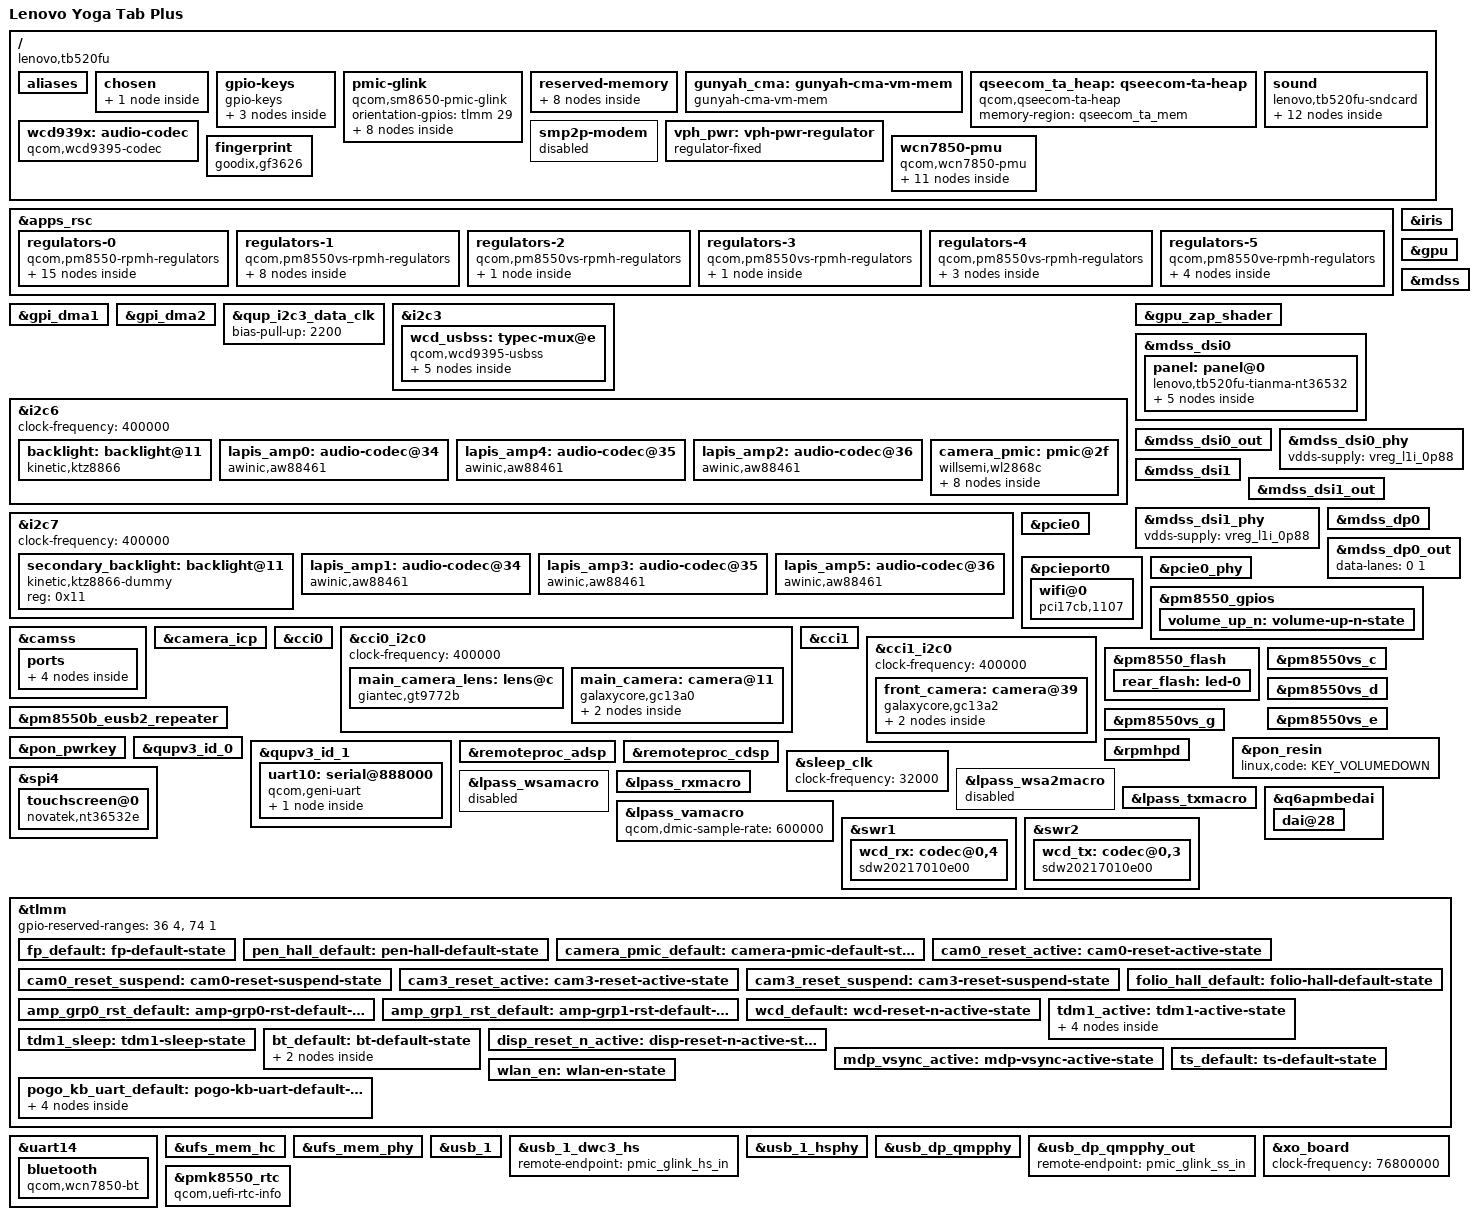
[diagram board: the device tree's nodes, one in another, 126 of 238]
// SPDX-License-Identifier: BSD-3-Clause
/*
 * Device Tree for Lenovo Yoga Tab Plus / YOGA Pad Pro (TB520FU, codename "lapis")
 * SoC: Qualcomm Snapdragon 8 Gen 3 Wi-Fi (APQ8650 / SM8650P, "pineapplep")
 *
 * Translated from Lenovo ZUI_18.5.10.037_260929_ROW downstream DTB/DTBO
 * (dtb_06 PineappleP v2 + dtbo_37 Lapis QRD) onto the mainline SM8650 /
 * Osilvfe caihong-v7.3 architecture.
 */

/dts-v1/;

#include <dt-bindings/arm/qcom,ids.h>
#include <dt-bindings/regulator/qcom,rpmh-regulator.h>
#include <dt-bindings/clock/qcom,sm8650-camcc.h>
#include <dt-bindings/gpio/gpio.h>
#include <dt-bindings/input/input.h>
#include <dt-bindings/leds/common.h>
#include <dt-bindings/sound/qcom,q6dsp-lpass-ports.h>
#include "sm8650.dtsi"
#include "pm8550.dtsi"
#include "pm8550b.dtsi"
#define PMK8550VE_SID 8
#include "pm8550ve.dtsi"
#include "pm8550vs.dtsi"
#include "pmk8550.dtsi"

/* Override upstream memory carveouts that differ on Lenovo lapis */
/delete-node/ &adspslpi_mem;
/delete-node/ &hwfence_shbuf;

/* Reclaim downstream Android Gunyah / QDSS reusable regions */
/delete-node/ &trust_ui_vm_mem;
/delete-node/ &oem_vm_mem;
/delete-node/ &qdss_mem;

/ {
	model = "Lenovo Yoga Tab Plus";
	compatible = "lenovo,tb520fu", "qcom,sm8650";
	chassis-type = "tablet";

	/* Lenovo ABL refuses to boot a DTB that does not match lapis QRD */
	qcom,msm-id = <QCOM_ID_SM8650 0x20000>, <QCOM_ID_SM8650 0x10000>,
		      <577 0x20000>, <577 0x10000>;
	qcom,board-id = <QCOM_BOARD_ID(QRD, 2, 0) 0>;

	/*
	 * Lenovo ABL compares this against the region stored on the device and
	 * powers off ("not compatible with hardware") if it is missing or differs.
	 */
	region_country = "ROW";

	aliases {
		serial0 = &uart15;
		serial1 = &uart14;
		serial2 = &uart10;
	};

	chosen {
		#address-cells = <2>;
		#size-cells = <2>;
		ranges;

		/*
		 * Phase 1 early bring-up framebuffer (ABL cont_splash_region):
		 * Enable status = "okay" below (and disable &mdss) when booting a
		 * headless/initramfs kernel before loading the NT36532 DRM panel driver.
		 * Resolution: 2944x1840 (or portrait 1840x2944 depending on ABL scanout),
		 * 32 bpp at physical address 0xd5100000 (carveout 0x2b00000).
		 */
		framebuffer0: framebuffer@d5100000 {
			compatible = "simple-framebuffer";
			reg = <0x0 0xd5100000 0x0 (2944 * 1840 * 4)>;
			width = <2944>;
			height = <1840>;
			stride = <(2944 * 4)>;
			format = "a8r8g8b8";
			memory-region = <&cont_splash_mem>;
			status = "disabled";
		};
	};

	/*
	 * No /hypervisor node. Gunyah recovers the resource-manager
	 * capabilities from XBL's merged tree (they change every boot), and
	 * a node at this path makes userspace treat the tablet as a VM.
	 */

	gpio-keys {
		compatible = "gpio-keys";

		pinctrl-0 = <&volume_up_n>, <&pen_hall_default>, <&folio_hall_default>;
		pinctrl-names = "default";

		key-volume-up {
			label = "Volume Up";
			linux,code = <KEY_VOLUMEUP>;
			gpios = <&pm8550_gpios 6 GPIO_ACTIVE_LOW>;
			debounce-interval = <15>;
			linux,can-disable;
			wakeup-source;
		};

		/*
		 * Downstream hall_detect@0 has two Hall sensors, TLMM 177 and
		 * 182. GPIO 177 goes low when the pen is docked on the tablet
		 * edge (verified on hardware), so it must not be reported as a
		 * lid switch: that makes userspace treat the built-in panel as
		 * closed whenever the pen is attached.
		 */
		event-hall-pen {
			label = "Pen Dock Hall Switch";
			gpios = <&tlmm 177 GPIO_ACTIVE_LOW>;
			linux,input-type = <EV_SW>;
			linux,code = <SW_PEN_INSERTED>;
			linux,can-disable;
		};

		/*
		 * GPIO 182 is the second stock Hall line (0xb6). Treated as the
		 * folio/cover lid; confirm with a magnetic cover before relying
		 * on logind HandleLidSwitch (keep ignore until verified).
		 */
		event-hall-folio {
			label = "Folio Cover Hall Switch";
			gpios = <&tlmm 182 GPIO_ACTIVE_LOW>;
			linux,input-type = <EV_SW>;
			linux,code = <SW_LID>;
			linux,can-disable;
			wakeup-source;
		};
	};

	/*
	 * Lenovo uses standard 45W USB-PD via Qualcomm SMB1396/PM8550B + ADSP battmgr
	 * (no proprietary SuperVOOC overrides needed).
	 */
	pmic-glink {
		compatible = "qcom,sm8650-pmic-glink",
			     "qcom,sm8550-pmic-glink",
			     "qcom,pmic-glink";
		#address-cells = <1>;
		#size-cells = <0>;
		orientation-gpios = <&tlmm 29 GPIO_ACTIVE_HIGH>;

		connector@0 {
			compatible = "usb-c-connector";
			reg = <0>;

			power-role = "dual";
			data-role = "dual";

			ports {
				#address-cells = <1>;
				#size-cells = <0>;

				port@0 {
					reg = <0>;

					pmic_glink_hs_in: endpoint {
						remote-endpoint = <&usb_1_dwc3_hs>;
					};
				};

				port@1 {
					reg = <1>;

					pmic_glink_ss_in: endpoint {
						remote-endpoint = <&usb_dp_qmpphy_out>;
					};
				};

				port@2 {
					reg = <2>;

					pmic_glink_sbu: endpoint {
						remote-endpoint = <&wcd_usbss_sbu_mux>;
					};
				};
			};
		};
	};

	reserved-memory {
		/*
		 * Downstream lost_reg_mem / ramoops carveouts from live_merged.dts
		 * (dtb_06 + dtbo_37). Missing no-map here lets the kernel map
		 * TrustZone/HYP-protected pages and can reset abl back to fastboot.
		 */
		lost_reg_mem: lost-reg-mem@9b09c000 {
			reg = <0x0 0x9b09c000 0x0 0x4000>;
			no-map;
		};

		ramoops@a2000000 {
			compatible = "ramoops";
			reg = <0x0 0xa2000000 0x0 0x400000>;
			console-size = <0x200000>;
			pmsg-size = <0x200000>;
			no-map;
		};

		/* Exact Lenovo lapis ADSP/SLPI carveout from dtb_06.dts (0x4080000) */
		adspslpi_mem: adspslpi@9df00000 {
			reg = <0x0 0x9df00000 0x0 0x4080000>;
			no-map;
		};

		/* Exact Lenovo lapis hwfence carveout from dtb_06.dts */
		hwfence_shbuf: hwfence-shbuf@d4e23000 {
			reg = <0x0 0xd4e23000 0x0 0x2dd000>;
			no-map;
		};

		/*
		 * Bootloader splash carveout from dtbo_37.dts fragment@73:
		 * reg = <0x0 0xd5100000 0x0 0x2b00000>;
		 * Keep reserved while testing simple-framebuffer; can be dropped once
		 * full DPU/NT36532 KMS takes over scanout cleanly.
		 */
		/*
		 * ABL looks this up by the exact path /reserved-memory/splash_region
		 * and powers the panel down before jumping to Linux if it is absent.
		 */
		cont_splash_mem: splash_region {
			label = "cont_splash_region";
			reg = <0x0 0xd5100000 0x0 0x2b00000>;
			no-map;
		};

		/* Exact Lenovo TZ merged region from dtb_06.dts */
		tz_merged_mem: tz-merged@d8000000 {
			reg = <0x0 0xd8000000 0x0 0x800000>;
			no-map;
		};

		gunyah_cma_mem: gunyah-cma-mem {
			compatible = "shared-dma-pool";
			alloc-ranges = <0x0 0x0 0x0 0xffffffff>;
			size = <0x0 0x4000000>;
			alignment = <0x0 0x200000>;
			reusable;
		};

		/*
		 * Staging heap for QSEE trusted-app images. The secure world
		 * accepts an image only from a 4 MiB-aligned region that has
		 * been shared as a whole, which is how Android's qseecom
		 * driver publishes qseecom_ta_region (16 MiB).
		 */
		qseecom_ta_mem: qseecom-ta-region {
			compatible = "shared-dma-pool";
			alloc-ranges = <0x0 0x0 0x0 0xffffffff>;
			size = <0x0 0x1000000>;
			alignment = <0x0 0x400000>;
			reusable;
		};
	};

	gunyah_cma: gunyah-cma-vm-mem {
		compatible = "gunyah-cma-vm-mem";
		memory-region = <&gunyah_cma_mem>;
		memory-region-names = "system-cma";
	};

	qseecom_ta_heap: qseecom-ta-heap {
		compatible = "qcom,qseecom-ta-heap";
		memory-region = <&qseecom_ta_mem>;
	};

	/*
	 * 6-Speaker Harman Kardon Audio (4 Woofers + 2 Tweeters):
	 * Driven by 6x Awinic AW882xx SmartPAs over Secondary TDM (SECONDARY_TDM_RX_0)
	 * + Qualcomm WCD939x SoundWire headset/USB-C analog codec + DMICs.
	 *
	 * Channel map from dtbo_37.dts fragments @64 & @65:
	 *   &i2c6: 0x34 -> ch0, 0x36 -> ch2, 0x35 -> ch4 (shared reset GPIO 128)
	 *   &i2c7: 0x34 -> ch1, 0x35 -> ch3, 0x36 -> ch5 (shared reset GPIO 28)
	 */
	sound {
		compatible = "lenovo,tb520fu-sndcard", "qcom,sm8650-sndcard";
		model = "Lenovo-TB520FU";
		audio-routing = "IN1_HPHL", "HPHL_OUT",
				"IN2_HPHR", "HPHR_OUT",
				"AMIC1", "MIC BIAS1",
				"AMIC3", "MIC BIAS3",
				"AMIC4", "MIC BIAS4",
				"AMIC5", "MIC BIAS3",
				"TX SWR_INPUT0", "ADC1_OUTPUT",
				"TX SWR_INPUT1", "ADC2_OUTPUT",
				"TX SWR_INPUT2", "ADC3_OUTPUT",
				"TX SWR_INPUT3", "ADC4_OUTPUT";

		wcd-playback-dai-link {
			link-name = "WCD Playback";

			cpu {
				sound-dai = <&q6apmbedai RX_CODEC_DMA_RX_0>;
			};

			codec {
				sound-dai = <&wcd939x 0>, <&swr1 0>, <&lpass_rxmacro 0>;
			};

			platform {
				sound-dai = <&q6apm>;
			};
		};

		wcd-capture-dai-link {
			link-name = "WCD Capture";

			cpu {
				sound-dai = <&q6apmbedai TX_CODEC_DMA_TX_3>;
			};

			codec {
				sound-dai = <&wcd939x 1>, <&swr2 0>, <&lpass_txmacro 0>;
			};

			platform {
				sound-dai = <&q6apm>;
			};
		};

		tdm-speaker-dai-link {
			link-name = "Secondary TDM Speakers";

			cpu {
				sound-dai = <&q6apmbedai SECONDARY_TDM_RX_0>;
			};

			codec {
				sound-dai = <&lapis_amp0>, <&lapis_amp1>,
					    <&lapis_amp2>, <&lapis_amp3>,
					    <&lapis_amp4>, <&lapis_amp5>;
			};

			platform {
				sound-dai = <&q6apm>;
			};
		};
	};

	wcd939x: audio-codec {
		compatible = "qcom,wcd9395-codec", "qcom,wcd9390-codec";

		pinctrl-0 = <&wcd_default>;
		pinctrl-names = "default";

		qcom,micbias1-microvolt = <1800000>;
		qcom,micbias2-microvolt = <1800000>;
		qcom,micbias3-microvolt = <1800000>;
		qcom,micbias4-microvolt = <1800000>;
		qcom,mbhc-buttons-vthreshold-microvolt = <75000 150000 237000 500000
							 500000 500000 500000 500000>;
		qcom,mbhc-headset-vthreshold-microvolt = <1700000>;
		qcom,mbhc-headphone-vthreshold-microvolt = <50000>;
		qcom,rx-device = <&wcd_rx>;
		qcom,tx-device = <&wcd_tx>;

		reset-gpios = <&tlmm 107 GPIO_ACTIVE_LOW>;

		vdd-buck-supply = <&vreg_l15b_1p8>;
		vdd-rxtx-supply = <&vreg_l15b_1p8>;
		vdd-io-supply = <&vreg_l15b_1p8>;
		vdd-mic-bias-supply = <&vreg_bob1>;

		#sound-dai-cells = <1>;
	};

	/* APQ8650 / SM8650P Wi-Fi-only tablet: disable cellular modem SMP2P */
	smp2p-modem {
		status = "disabled";
	};

	vph_pwr: vph-pwr-regulator {
		compatible = "regulator-fixed";

		regulator-name = "vph_pwr";
		regulator-min-microvolt = <3700000>;
		regulator-max-microvolt = <3700000>;

		regulator-always-on;
		regulator-boot-on;
	};

	/* Qualcomm FastConnect 7800 (WCN7850 / "kiwi_v2") PMU */
	wcn7850-pmu {
		compatible = "qcom,wcn7850-pmu";

		pinctrl-names = "default";
		pinctrl-0 = <&wlan_en>, <&bt_default>;

		wlan-enable-gpios = <&tlmm 16 GPIO_ACTIVE_HIGH>;
		bt-enable-gpios = <&tlmm 17 GPIO_ACTIVE_HIGH>;

		vdd-supply = <&vreg_s4i_0p85>;
		vddio-supply = <&vreg_l15b_1p8>;
		vddio1p2-supply = <&vreg_l3c_1p2>;
		vddaon-supply = <&vreg_s2c_0p8>;
		vdddig-supply = <&vreg_s3c_0p9>;
		vddrfa1p2-supply = <&vreg_s1c_1p2>;
		vddrfa1p8-supply = <&vreg_s6c_1p8>;

		clocks = <&rpmhcc RPMH_RF_CLK1>;

		regulators {
			vreg_pmu_rfa_cmn: ldo0 {
				regulator-name = "vreg_pmu_rfa_cmn";
			};

			vreg_pmu_aon_0p59: ldo1 {
				regulator-name = "vreg_pmu_aon_0p59";
			};

			vreg_pmu_wlcx_0p8: ldo2 {
				regulator-name = "vreg_pmu_wlcx_0p8";
			};

			vreg_pmu_wlmx_0p85: ldo3 {
				regulator-name = "vreg_pmu_wlmx_0p85";
			};

			vreg_pmu_btcmx_0p85: ldo4 {
				regulator-name = "vreg_pmu_btcmx_0p85";
			};

			vreg_pmu_rfa_0p8: ldo5 {
				regulator-name = "vreg_pmu_rfa_0p8";
			};

			vreg_pmu_rfa_1p2: ldo6 {
				regulator-name = "vreg_pmu_rfa_1p2";
			};

			vreg_pmu_rfa_1p8: ldo7 {
				regulator-name = "vreg_pmu_rfa_1p8";
			};

			vreg_pmu_pcie_0p9: ldo8 {
				regulator-name = "vreg_pmu_pcie_0p9";
			};

			vreg_pmu_pcie_1p8: ldo9 {
				regulator-name = "vreg_pmu_pcie_1p8";
			};
		};
	};
};

/*
 * All regulator voltage limits below match Lenovo's dtb_06.dts + dtbo_37.dts
 * ground truth to the exact microvolt.
 */
&apps_rsc {
	regulators-0 {
		compatible = "qcom,pm8550-rpmh-regulators";

		vdd-bob1-supply = <&vph_pwr>;
		vdd-bob2-supply = <&vph_pwr>;
		vdd-l2-l13-l14-supply = <&vreg_bob1>;
		vdd-l3-supply = <&vreg_s1c_1p2>;
		vdd-l5-l16-supply = <&vreg_bob1>;
		vdd-l6-l7-supply = <&vreg_bob1>;
		vdd-l8-l9-supply = <&vreg_bob1>;
		vdd-l11-supply = <&vreg_s1c_1p2>;
		vdd-l12-supply = <&vreg_s6c_1p8>;
		vdd-l15-supply = <&vreg_s6c_1p8>;
		vdd-l17-supply = <&vreg_bob2>;

		qcom,pmic-id = "b";

		vreg_bob1: bob1 {
			regulator-name = "vreg_bob1";
			regulator-min-microvolt = <3008000>;
			regulator-max-microvolt = <3960000>;
			regulator-initial-mode = <RPMH_REGULATOR_MODE_HPM>;
		};

		vreg_bob2: bob2 {
			regulator-name = "vreg_bob2";
			regulator-min-microvolt = <2704000>;
			regulator-max-microvolt = <3008000>;
			regulator-initial-mode = <RPMH_REGULATOR_MODE_HPM>;
		};

		vreg_l1b_1p8: ldo1 {
			regulator-name = "vreg_l1b_1p8";
			regulator-min-microvolt = <1800000>;
			regulator-max-microvolt = <1800000>;
			regulator-initial-mode = <RPMH_REGULATOR_MODE_HPM>;
			regulator-always-on;
		};

		vreg_l2b_3p0: ldo2 {
			regulator-name = "vreg_l2b_3p0";
			regulator-min-microvolt = <3008000>;
			regulator-max-microvolt = <3008000>;
			regulator-initial-mode = <RPMH_REGULATOR_MODE_HPM>;
			regulator-allow-set-load;
			regulator-allowed-modes = <RPMH_REGULATOR_MODE_LPM
						   RPMH_REGULATOR_MODE_HPM>;
		};

		vreg_l5b_3p1: ldo5 {
			regulator-name = "vreg_l5b_3p1";
			regulator-min-microvolt = <3104000>;
			regulator-max-microvolt = <3104000>;
			regulator-initial-mode = <RPMH_REGULATOR_MODE_HPM>;
			regulator-allow-set-load;
			regulator-allowed-modes = <RPMH_REGULATOR_MODE_LPM
						   RPMH_REGULATOR_MODE_HPM>;
		};

		vreg_l8b_1p8: ldo8 {
			regulator-name = "vreg_l8b_1p8";
			regulator-min-microvolt = <1800000>;
			regulator-max-microvolt = <3008000>;
			regulator-initial-mode = <RPMH_REGULATOR_MODE_HPM>;
			regulator-allow-set-load;
			regulator-allowed-modes = <RPMH_REGULATOR_MODE_LPM
						   RPMH_REGULATOR_MODE_HPM>;
		};

		vreg_l9b_2p96: ldo9 {
			regulator-name = "vreg_l9b_2p96";
			regulator-min-microvolt = <2960000>;
			regulator-max-microvolt = <3008000>;
			regulator-initial-mode = <RPMH_REGULATOR_MODE_HPM>;
			regulator-allow-set-load;
			regulator-allowed-modes = <RPMH_REGULATOR_MODE_LPM
						   RPMH_REGULATOR_MODE_HPM>;
		};

		vreg_l10b_1p8: ldo10 {
			regulator-name = "vreg_l10b_1p8";
			regulator-min-microvolt = <1800000>;
			regulator-max-microvolt = <1800000>;
			regulator-initial-mode = <RPMH_REGULATOR_MODE_HPM>;
			regulator-allow-set-load;
			regulator-allowed-modes = <RPMH_REGULATOR_MODE_LPM
						   RPMH_REGULATOR_MODE_HPM>;
		};

		/* Panel VDD (1.2 V) */
		vreg_l11b_1p2: ldo11 {
			regulator-name = "vreg_l11b_1p2";
			regulator-min-microvolt = <1200000>;
			regulator-max-microvolt = <1200000>;
			regulator-initial-mode = <RPMH_REGULATOR_MODE_HPM>;
			regulator-allow-set-load;
			regulator-allowed-modes = <RPMH_REGULATOR_MODE_LPM
						   RPMH_REGULATOR_MODE_HPM>;
		};

		/*
		 * Panel VDDIO. Stock Android votes 1.952 V, but L12B is fed from
		 * S6C (1.856 V) and enabling it at 1.952 V hard-resets the SoC.
		 */
		vreg_l12b_1p8: ldo12 {
			regulator-name = "vreg_l12b_1p8";
			regulator-min-microvolt = <1800000>;
			regulator-max-microvolt = <1800000>;
			regulator-initial-mode = <RPMH_REGULATOR_MODE_HPM>;
			regulator-allow-set-load;
			regulator-allowed-modes = <RPMH_REGULATOR_MODE_LPM
						   RPMH_REGULATOR_MODE_HPM>;
		};

		/* Panel VCI (3.0 V) */
		vreg_l13b_3p0: ldo13 {
			regulator-name = "vreg_l13b_3p0";
			regulator-min-microvolt = <3000000>;
			regulator-max-microvolt = <3000000>;
			regulator-initial-mode = <RPMH_REGULATOR_MODE_HPM>;
			regulator-allow-set-load;
			regulator-allowed-modes = <RPMH_REGULATOR_MODE_LPM
						   RPMH_REGULATOR_MODE_HPM>;
		};

		vreg_l14b_3p2: ldo14 {
			regulator-name = "vreg_l14b_3p2";
			regulator-min-microvolt = <3200000>;
			regulator-max-microvolt = <3200000>;
			regulator-initial-mode = <RPMH_REGULATOR_MODE_HPM>;
			regulator-always-on;
		};

		vreg_l15b_1p8: ldo15 {
			regulator-name = "vreg_l15b_1p8";
			regulator-min-microvolt = <1800000>;
			regulator-max-microvolt = <1800000>;
			regulator-initial-mode = <RPMH_REGULATOR_MODE_HPM>;
			regulator-allow-set-load;
			regulator-allowed-modes = <RPMH_REGULATOR_MODE_LPM
						   RPMH_REGULATOR_MODE_HPM>;
		};

		vreg_l16b_2p8: ldo16 {
			regulator-name = "vreg_l16b_2p8";
			regulator-min-microvolt = <2800000>;
			regulator-max-microvolt = <2800000>;
			regulator-initial-mode = <RPMH_REGULATOR_MODE_HPM>;
			regulator-allow-set-load;
			regulator-allowed-modes = <RPMH_REGULATOR_MODE_LPM
						   RPMH_REGULATOR_MODE_HPM>;
		};

		/* UFS 4.0 VCC (2.504 V) */
		vreg_l17b_2p5: ldo17 {
			regulator-name = "vreg_l17b_2p5";
			regulator-min-microvolt = <2504000>;
			regulator-max-microvolt = <2504000>;
			regulator-initial-mode = <RPMH_REGULATOR_MODE_HPM>;
			regulator-allow-set-load;
			regulator-allowed-modes = <RPMH_REGULATOR_MODE_LPM
						   RPMH_REGULATOR_MODE_HPM>;
		};
	};

	regulators-1 {
		compatible = "qcom,pm8550vs-rpmh-regulators";

		vdd-l1-supply = <&vreg_s1c_1p2>;
		vdd-l2-supply = <&vreg_s1c_1p2>;
		vdd-l3-supply = <&vreg_s1c_1p2>;
		vdd-s1-supply = <&vph_pwr>;
		vdd-s2-supply = <&vph_pwr>;
		vdd-s3-supply = <&vph_pwr>;
		vdd-s4-supply = <&vph_pwr>;
		vdd-s5-supply = <&vph_pwr>;
		vdd-s6-supply = <&vph_pwr>;

		qcom,pmic-id = "c";

		vreg_s1c_1p2: smps1 {
			regulator-name = "vreg_s1c_1p2";
			regulator-min-microvolt = <1224000>;
			regulator-max-microvolt = <1348000>;
			regulator-initial-mode = <RPMH_REGULATOR_MODE_HPM>;
		};

		vreg_s2c_0p8: smps2 {
			regulator-name = "vreg_s2c_0p8";
			regulator-min-microvolt = <852000>;
			regulator-max-microvolt = <1036000>;
			regulator-initial-mode = <RPMH_REGULATOR_MODE_HPM>;
		};

		vreg_s3c_0p9: smps3 {
			regulator-name = "vreg_s3c_0p9";
			regulator-min-microvolt = <904000>;
			regulator-max-microvolt = <1064000>;
			regulator-initial-mode = <RPMH_REGULATOR_MODE_HPM>;
		};

		vreg_s4c_1p2: smps4 {
			regulator-name = "vreg_s4c_1p2";
			regulator-min-microvolt = <1200000>;
			regulator-max-microvolt = <1280000>;
			regulator-initial-mode = <RPMH_REGULATOR_MODE_HPM>;
		};

		vreg_s5c_0p7: smps5 {
			regulator-name = "vreg_s5c_0p7";
			regulator-min-microvolt = <752000>;
			regulator-max-microvolt = <900000>;
			regulator-initial-mode = <RPMH_REGULATOR_MODE_HPM>;
		};

		vreg_s6c_1p8: smps6 {
			regulator-name = "vreg_s6c_1p8";
			regulator-min-microvolt = <1856000>;
			regulator-max-microvolt = <2000000>;
			regulator-initial-mode = <RPMH_REGULATOR_MODE_HPM>;
		};

		/* UFS 4.0 VCCQ (1.2 V) */
		vreg_l1c_1p2: ldo1 {
			regulator-name = "vreg_l1c_1p2";
			regulator-min-microvolt = <1200000>;
			regulator-max-microvolt = <1200000>;
			regulator-initial-mode = <RPMH_REGULATOR_MODE_HPM>;
			regulator-allow-set-load;
			regulator-allowed-modes = <RPMH_REGULATOR_MODE_LPM
						   RPMH_REGULATOR_MODE_HPM>;
		};

		vreg_l3c_1p2: ldo3 {
			regulator-name = "vreg_l3c_1p2";
			regulator-min-microvolt = <1200000>;
			regulator-max-microvolt = <1200000>;
			regulator-initial-mode = <RPMH_REGULATOR_MODE_HPM>;
			regulator-allow-set-load;
			regulator-allowed-modes = <RPMH_REGULATOR_MODE_LPM
						   RPMH_REGULATOR_MODE_HPM>;
		};
	};

	regulators-2 {
		compatible = "qcom,pm8550vs-rpmh-regulators";

		vdd-l1-supply = <&vreg_s3c_0p9>;

		qcom,pmic-id = "d";

		vreg_l1d_0p88: ldo1 {
			regulator-name = "vreg_l1d_0p88";
			regulator-min-microvolt = <880000>;
			regulator-max-microvolt = <920000>;
			regulator-initial-mode = <RPMH_REGULATOR_MODE_HPM>;
			regulator-allow-set-load;
			regulator-allowed-modes = <RPMH_REGULATOR_MODE_LPM
						   RPMH_REGULATOR_MODE_HPM>;
		};
	};

	regulators-3 {
		compatible = "qcom,pm8550vs-rpmh-regulators";

		vdd-l3-supply = <&vreg_s3c_0p9>;

		qcom,pmic-id = "e";

		vreg_l3e_0p9: ldo3 {
			regulator-name = "vreg_l3e_0p9";
			regulator-min-microvolt = <880000>;
			regulator-max-microvolt = <920000>;
			regulator-initial-mode = <RPMH_REGULATOR_MODE_HPM>;
			regulator-allow-set-load;
			regulator-allowed-modes = <RPMH_REGULATOR_MODE_LPM
						   RPMH_REGULATOR_MODE_HPM>;
		};
	};

	regulators-4 {
		compatible = "qcom,pm8550vs-rpmh-regulators";

		vdd-l1-supply = <&vreg_s3c_0p9>;
		vdd-l2-supply = <&vreg_s1c_1p2>;
		vdd-l3-supply = <&vreg_s3c_0p9>;

		qcom,pmic-id = "g";

		vreg_l1g_0p91: ldo1 {
			regulator-name = "vreg_l1g_0p91";
			regulator-min-microvolt = <912000>;
			regulator-max-microvolt = <920000>;
			regulator-initial-mode = <RPMH_REGULATOR_MODE_HPM>;
			regulator-allow-set-load;
			regulator-allowed-modes = <RPMH_REGULATOR_MODE_LPM
						   RPMH_REGULATOR_MODE_HPM>;
		};

		vreg_l2g_1p2: ldo2 {
			regulator-name = "vreg_l2g_1p2";
			regulator-min-microvolt = <1200000>;
			regulator-max-microvolt = <1200000>;
			regulator-initial-mode = <RPMH_REGULATOR_MODE_HPM>;
			regulator-allow-set-load;
			regulator-allowed-modes = <RPMH_REGULATOR_MODE_LPM
						   RPMH_REGULATOR_MODE_HPM>;
		};

		vreg_l3g_0p91: ldo3 {
			regulator-name = "vreg_l3g_0p91";
			regulator-min-microvolt = <880000>;
			regulator-max-microvolt = <912000>;
			regulator-initial-mode = <RPMH_REGULATOR_MODE_HPM>;
			regulator-allow-set-load;
			regulator-allowed-modes = <RPMH_REGULATOR_MODE_LPM
						   RPMH_REGULATOR_MODE_HPM>;
		};
	};

	regulators-5 {
		compatible = "qcom,pm8550ve-rpmh-regulators";

		vdd-l1-supply = <&vreg_s3c_0p9>;
		vdd-l2-supply = <&vreg_s3c_0p9>;
		vdd-l3-supply = <&vreg_s1c_1p2>;
		vdd-s4-supply = <&vph_pwr>;

		qcom,pmic-id = "i";

		vreg_s4i_0p85: smps4 {
			regulator-name = "vreg_s4i_0p85";
			regulator-min-microvolt = <852000>;
			regulator-max-microvolt = <1004000>;
			regulator-initial-mode = <RPMH_REGULATOR_MODE_HPM>;
		};

		vreg_l1i_0p88: ldo1 {
			regulator-name = "vreg_l1i_0p88";
			regulator-min-microvolt = <880000>;
			regulator-max-microvolt = <912000>;
			regulator-initial-mode = <RPMH_REGULATOR_MODE_HPM>;
			regulator-allow-set-load;
			regulator-allowed-modes = <RPMH_REGULATOR_MODE_LPM
						   RPMH_REGULATOR_MODE_HPM>;
		};

		vreg_l2i_0p88: ldo2 {
			regulator-name = "vreg_l2i_0p88";
			regulator-min-microvolt = <880000>;
			regulator-max-microvolt = <912000>;
			regulator-initial-mode = <RPMH_REGULATOR_MODE_HPM>;
			regulator-allow-set-load;
			regulator-allowed-modes = <RPMH_REGULATOR_MODE_LPM
						   RPMH_REGULATOR_MODE_HPM>;
		};

		vreg_l3i_1p2: ldo3 {
			regulator-name = "vreg_l3i_1p2";
			regulator-min-microvolt = <1200000>;
			regulator-max-microvolt = <1200000>;
			regulator-initial-mode = <RPMH_REGULATOR_MODE_HPM>;
			regulator-allow-set-load;
			regulator-allowed-modes = <RPMH_REGULATOR_MODE_LPM
						   RPMH_REGULATOR_MODE_HPM>;
		};
	};
};

&gpi_dma1 {
	status = "okay";
};

&gpi_dma2 {
	status = "okay";
};

&qup_i2c3_data_clk {
	bias-pull-up = <2200>;
};

/* QUPv3 WRAP1 SE3 (0xa8c000): WCD939x USB-C SBU & analog audio switch */
&i2c3 {
	status = "okay";

	wcd_usbss: typec-mux@e {
		compatible = "qcom,wcd9395-usbss", "qcom,wcd9390-usbss";
		reg = <0xe>;

		vdd-supply = <&vreg_l15b_1p8>;

		mode-switch;
		orientation-switch;

		ports {
			#address-cells = <1>;
			#size-cells = <0>;

			port@0 {
				reg = <0>;

				wcd_usbss_sbu_mux: endpoint {
					remote-endpoint = <&pmic_glink_sbu>;
				};
			};

			port@1 {
				reg = <1>;

				wcd_usbss_headset_out: endpoint {};
			};
		};
	};
};

/*
 * QUPv3 WRAP1 SE6 (0xa98000):
 * - Primary Kinetic KTZ8866 backlight + LCD VSP/VSN bias IC (@0x11)
 * - 3x Awinic AW882xx SmartPA speaker amps (@0x34 ch0, @0x36 ch2, @0x35 ch4)
 * - Parade PS5169 USB 3.2 / DP linear redriver (@0x30)
 */
&i2c6 {
	clock-frequency = <400000>;
	status = "okay";

	backlight: backlight@11 {
		compatible = "kinetic,ktz8866";
		reg = <0x11>;

		/*
		 * Values from the stock "lenovo,ktz8866" init-cmds:
		 * 0x0c=0x2e 0x0d/0x0e=0x24 (5.8 V) 0x03=0xc5 0x02=0xfb
		 * 0x14=0x88 0x15=0x9d 0x08=0x7f (all six LED strings).
		 * Only the primary IC supplies the LCD bias rails.
		 */
		vddpos-microvolt = <5800000>;
		vddneg-microvolt = <5800000>;
		current-num-sinks = <6>;
		kinetic,bl-cfg1 = <0xfb>;
		kinetic,bl-cfg2 = <0xc5>;
		kinetic,bl-dimming = <0x88>;
		kinetic,pwm-ramp-time = <0x9d>;
		kinetic,lcd-boost-cfg = <0x2e>;
		kinetic,lcd-bias-primary-only;
		kinetic,current-ramp-delay-ms = <128>;
		kinetic,led-enable-ramp-delay-ms = <1>;
		kinetic,enable-lcd-bias;

		enable-gpios = <&tlmm 82 GPIO_ACTIVE_HIGH>;
		enp-gpios = <&tlmm 72 GPIO_ACTIVE_HIGH>;
		enn-gpios = <&tlmm 73 GPIO_ACTIVE_HIGH>;

		secondary = <&secondary_backlight>;
	};

	/*
	 * Note: On Lenovo lapis, amp0/amp2/amp4 share reset GPIO 128 ("one_rst_flag = 1").
	 * Pull GPIO 128 high via pinctrl (&amp_grp0_rst_default) rather than assigning the
	 * same exclusive gpiod descriptor to three sibling I2C devices.
	 */
	lapis_amp0: audio-codec@34 {
		compatible = "awinic,aw88461";
		reg = <0x34>;
		#sound-dai-cells = <0>;
		dvdd-supply = <&vreg_l15b_1p8>;
		firmware-name = "awinic/tb520fu-aw882xx-acf.bin";
		awinic,audio-channel = <0>;
		awinic,sync-flag;
		pinctrl-0 = <&amp_grp0_rst_default>;
		pinctrl-names = "default";
		sound-name-prefix = "Amp0";
	};

	lapis_amp4: audio-codec@35 {
		compatible = "awinic,aw88461";
		reg = <0x35>;
		#sound-dai-cells = <0>;
		dvdd-supply = <&vreg_l15b_1p8>;
		firmware-name = "awinic/tb520fu-aw882xx-acf.bin";
		awinic,audio-channel = <4>;
		awinic,sync-flag;
		sound-name-prefix = "Amp4";
	};

	lapis_amp2: audio-codec@36 {
		compatible = "awinic,aw88461";
		reg = <0x36>;
		#sound-dai-cells = <0>;
		dvdd-supply = <&vreg_l15b_1p8>;
		firmware-name = "awinic/tb520fu-aw882xx-acf.bin";
		awinic,audio-channel = <2>;
		awinic,sync-flag;
		sound-name-prefix = "Amp2";
	};

	/*
	 * Camera PMIC (stock qcom,ic_wl2868c @0x2f, en-gpio TLMM 5).
	 * LDO map for the main OV13B10 follows the usual WL2868C rear-camera
	 * layout (DVDD/AVDD/DOVDD); voltages match Omnivision's nominal rails.
	 */
	camera_pmic: pmic@2f {
		compatible = "willsemi,wl2868c";
		reg = <0x2f>;
		reset-gpios = <&tlmm 5 GPIO_ACTIVE_LOW>;
		pinctrl-names = "default";
		pinctrl-0 = <&camera_pmic_default>;

		vin12-supply = <&vreg_l15b_1p8>;
		vin34-supply = <&vreg_bob1>;
		vin5-supply = <&vreg_bob1>;
		vin6-supply = <&vreg_bob1>;
		vin7-supply = <&vreg_bob1>;

		regulators {
			camera_ldo1: ldo1 {
				regulator-name = "camera_ldo1";
				regulator-min-microvolt = <1200000>;
				regulator-max-microvolt = <1200000>;
			};

			camera_ldo2: ldo2 {
				regulator-name = "camera_ldo2";
				regulator-min-microvolt = <1200000>;
				regulator-max-microvolt = <1200000>;
			};

			camera_ldo3: ldo3 {
				regulator-name = "camera_ldo3";
				regulator-min-microvolt = <2800000>;
				regulator-max-microvolt = <2800000>;
			};

			camera_ldo4: ldo4 {
				regulator-name = "camera_ldo4";
				regulator-min-microvolt = <2800000>;
				regulator-max-microvolt = <2800000>;
			};

			camera_ldo5: ldo5 {
				regulator-name = "camera_ldo5";
				regulator-min-microvolt = <2800000>;
				regulator-max-microvolt = <2800000>;
			};

			camera_ldo6: ldo6 {
				regulator-name = "camera_ldo6";
				regulator-min-microvolt = <2800000>;
				regulator-max-microvolt = <2800000>;
			};

			camera_ldo7: ldo7 {
				regulator-name = "camera_ldo7";
				regulator-min-microvolt = <1800000>;
				regulator-max-microvolt = <1800000>;
			};
		};
	};
};

/*
 * QUPv3 WRAP1 SE7 (0xa9c000):
 * - Secondary Kinetic KTZ8866 backlight IC (@0x11)
 * - 3x Awinic AW882xx SmartPA speaker amps (@0x34 ch1, @0x35 ch3, @0x36 ch5)
 *   sharing reset GPIO 28 ("one_rst_flag = 2")
 */
&i2c7 {
	clock-frequency = <400000>;
	status = "okay";

	secondary_backlight: backlight@11 {
		compatible = "kinetic,ktz8866-dummy";
		reg = <0x11>;
	};

	lapis_amp1: audio-codec@34 {
		compatible = "awinic,aw88461";
		reg = <0x34>;
		#sound-dai-cells = <0>;
		dvdd-supply = <&vreg_l15b_1p8>;
		firmware-name = "awinic/tb520fu-aw882xx-acf.bin";
		awinic,audio-channel = <1>;
		awinic,sync-flag;
		pinctrl-0 = <&amp_grp1_rst_default>;
		pinctrl-names = "default";
		sound-name-prefix = "Amp1";
	};

	lapis_amp3: audio-codec@35 {
		compatible = "awinic,aw88461";
		reg = <0x35>;
		#sound-dai-cells = <0>;
		dvdd-supply = <&vreg_l15b_1p8>;
		firmware-name = "awinic/tb520fu-aw882xx-acf.bin";
		awinic,audio-channel = <3>;
		awinic,sync-flag;
		sound-name-prefix = "Amp3";
	};

	lapis_amp5: audio-codec@36 {
		compatible = "awinic,aw88461";
		reg = <0x36>;
		#sound-dai-cells = <0>;
		dvdd-supply = <&vreg_l15b_1p8>;
		firmware-name = "awinic/tb520fu-aw882xx-acf.bin";
		awinic,audio-channel = <5>;
		awinic,sync-flag;
		sound-name-prefix = "Amp5";
	};
};

&iris {
	firmware-name = "qcom/sm8650/lenovo/tb520fu/vpu33_4v.mbn";

	status = "okay";
};

&gpu {
	status = "okay";
};

/*
 * Note: Lenovo names the signed Adreno 750 zap shader "gen70900_zap.mbn"
 * inside /vendor/firmware/ on stock ZUI_18.5.10.037_260929_ROW.
 */
&gpu_zap_shader {
	firmware-name = "qcom/sm8650/lenovo/tb520fu/gen70900_zap.mbn";
};

&mdss {
	status = "okay";
};

&mdss_dsi0 {
	vdda-supply = <&vreg_l3i_1p2>;

	qcom,dual-dsi-mode;
	qcom,sync-dual-dsi;
	qcom,master-dsi;

	status = "okay";

	/*
	 * Active panel on HA25BC37 (/proc/cmdline):
	 *   qcom,mdss_dsi_panel_lapis_tianma_nt36532_dsc_3k_video
	 * Second-source panel (if needed on BOE units):
	 *   "lenovo,tb520fu-boe-nt36532"
	 */
	panel: panel@0 {
		compatible = "lenovo,tb520fu-tianma-nt36532";
		reg = <0>;

		backlight = <&backlight>;

		reset-gpios = <&tlmm 133 GPIO_ACTIVE_LOW>;

		vddio-supply = <&vreg_l12b_1p8>;
		vdd-supply = <&vreg_l11b_1p2>;
		vci-supply = <&vreg_l13b_3p0>;

		pinctrl-0 = <&disp_reset_n_active>, <&mdp_vsync_active>;
		pinctrl-names = "default";

		ports {
			#address-cells = <1>;
			#size-cells = <0>;

			port@0 {
				reg = <0>;

				panel_in_0: endpoint {
					remote-endpoint = <&mdss_dsi0_out>;
				};
			};

			port@1 {
				reg = <1>;

				panel_in_1: endpoint {
					remote-endpoint = <&mdss_dsi1_out>;
				};
			};
		};
	};
};

&mdss_dsi0_out {
	remote-endpoint = <&panel_in_0>;
	data-lanes = <0 1 2 3>;
};

&mdss_dsi0_phy {
	vdds-supply = <&vreg_l1i_0p88>;

	status = "okay";
};

&mdss_dsi1 {
	vdda-supply = <&vreg_l3i_1p2>;

	qcom,dual-dsi-mode;
	qcom,sync-dual-dsi;

	status = "okay";

	assigned-clock-parents = <&mdss_dsi0_phy DSI_BYTE_PLL_CLK>,
				 <&mdss_dsi0_phy DSI_PIXEL_PLL_CLK>;
};

&mdss_dsi1_out {
	remote-endpoint = <&panel_in_1>;
	data-lanes = <0 1 2 3>;
};

&mdss_dsi1_phy {
	vdds-supply = <&vreg_l1i_0p88>;

	status = "okay";
};

&mdss_dp0 {
	status = "okay";
};

&mdss_dp0_out {
	data-lanes = <0 1>;
};

&pcie0 {
	iommu-map = <0 &apps_smmu 0x1400 0x1>,
		    <0x100 &apps_smmu 0x1401 0x1>;

	wake-gpios = <&tlmm 96 GPIO_ACTIVE_HIGH>;
	perst-gpios = <&tlmm 94 GPIO_ACTIVE_LOW>;

	pinctrl-0 = <&pcie0_default_state>;
	pinctrl-names = "default";

	status = "okay";
};

&pcieport0 {
	wifi@0 {
		compatible = "pci17cb,1107";
		reg = <0x10000 0x0 0x0 0x0 0x0>;
		firmware-name = "tb520fu";

		vddrfacmn-supply = <&vreg_pmu_rfa_cmn>;
		vddaon-supply = <&vreg_pmu_aon_0p59>;
		vddwlcx-supply = <&vreg_pmu_wlcx_0p8>;
		vddwlmx-supply = <&vreg_pmu_wlmx_0p85>;
		vddrfa0p8-supply = <&vreg_pmu_rfa_0p8>;
		vddrfa1p2-supply = <&vreg_pmu_rfa_1p2>;
		vddrfa1p8-supply = <&vreg_pmu_rfa_1p8>;
		vddpcie0p9-supply = <&vreg_pmu_pcie_0p9>;
		vddpcie1p8-supply = <&vreg_pmu_pcie_1p8>;
	};
};

&pcie0_phy {
	vdda-phy-supply = <&vreg_l1i_0p88>;
	vdda-pll-supply = <&vreg_l3i_1p2>;

	status = "okay";
};

&pm8550_gpios {
	volume_up_n: volume-up-n-state {
		pins = "gpio6";
		function = "normal";
		bias-pull-up;
		input-enable;
		power-source = <1>;
	};
};

/*
 * Main rear camera (stock qcom,cam-sensor0):
 *   CCI0 master 0, CSIPHY4, MCLK0 @ GPIO100 / 19.2 MHz, reset GPIO7.
 * Front camera (stock qcom,cam-sensor1, the one facing the user):
 *   CCI1 master 0, CSIPHY0, MCLK3 @ GPIO103 / 19.2 MHz, reset GPIO109.
 * The rear SC202CS macro (stock qcom,cam-sensor2: CCI0 master 1, CSIPHY1,
 * MCLK1 @ GPIO101, reset GPIO15) is left out until it has a driver.
 */
&camss {
	vdd-csiphy01-0p9-supply = <&vreg_l2i_0p88>;
	vdd-csiphy01-1p2-supply = <&vreg_l3i_1p2>;
	vdd-csiphy24-0p9-supply = <&vreg_l2i_0p88>;
	vdd-csiphy24-1p2-supply = <&vreg_l3i_1p2>;
	status = "okay";

	ports {
		#address-cells = <1>;
		#size-cells = <0>;

		port@0 {
			reg = <0>;

			lapis_csiphy0_ep: endpoint {
				clock-lanes = <7>;
				data-lanes = <0 1 2 3>;
				remote-endpoint = <&lapis_front_cam_ep>;
			};
		};

		port@4 {
			reg = <4>;

			lapis_csiphy4_ep: endpoint {
				clock-lanes = <7>;
				data-lanes = <0 1 2 3>;
				remote-endpoint = <&lapis_main_cam_ep>;
			};
		};
	};
};

&camera_icp {
	/* LPDDR5X values shared with SM8650 camera boards (caihong/elden). */
	qcom,ubwc-configuration = <0x7083 0x1620f 0x7083 0x1620f>;
	firmware-name = "qcom/sm8650/lenovo/tb520fu/camera_icp.mbn";
	status = "okay";
};

&cci0 {
	status = "okay";
};

&cci0_i2c0 {
	#address-cells = <1>;
	#size-cells = <0>;
	clock-frequency = <400000>;

	/*
	 * This unit probes as LCE GC13A0 at 0x11 (chip id 0x13a0). The alternate
	 * TXD OV13B10 SKU uses 0x36 and is not present here.
	 */
	/*
	 * Voice-coil focus actuator of the main camera module. The vendor
	 * power sequence feeds it from WL2868C LDO5 alone.
	 */
	main_camera_lens: lens@c {
		compatible = "giantec,gt9772b";
		reg = <0x0c>;
		vaf-supply = <&camera_ldo5>;
	};

	main_camera: camera@11 {
		compatible = "galaxycore,gc13a0";
		reg = <0x11>;
		orientation = <1>;
		/* The panel is landscape and the sensor is mounted upright. */
		rotation = <0>;

		clocks = <&camcc CAM_CC_MCLK0_CLK>;
		assigned-clocks = <&camcc CAM_CC_MCLK0_CLK>;
		assigned-clock-rates = <19200000>;
		power-domains = <&camcc CAM_CC_TITAN_TOP_GDSC>;

		reset-gpios = <&tlmm 7 GPIO_ACTIVE_LOW>;
		pinctrl-0 = <&cam0_default>, <&cam0_reset_active>;
		pinctrl-1 = <&cam0_sleep>, <&cam0_reset_suspend>;
		pinctrl-names = "default", "sleep";

		dovdd-supply = <&camera_ldo7>;
		avdd-supply = <&camera_ldo4>;
		dvdd-supply = <&camera_ldo1>;
		flash-leds = <&rear_flash>;
		lens-focus = <&main_camera_lens>;

		port {
			lapis_main_cam_ep: endpoint {
				clock-lanes = <7>;
				data-lanes = <0 1 2 3>;
				link-frequencies = /bits/ 64 <590400000 302400000>;
				remote-endpoint = <&lapis_csiphy4_ep>;
			};
		};
	};
};

&cci1 {
	/* Only master 0 is wired up on this board. */
	pinctrl-0 = <&cci1_0_default>;
	pinctrl-1 = <&cci1_0_sleep>;
	status = "okay";
};

&cci1_i2c0 {
	#address-cells = <1>;
	#size-cells = <0>;
	clock-frequency = <400000>;

	/*
	 * GC13A2 (chip id 0x13a2). The vendor power sequence lists WL2868C
	 * LDO2 with value 0, but the sensor does not answer without it.
	 */
	front_camera: camera@39 {
		compatible = "galaxycore,gc13a2";
		reg = <0x39>;
		orientation = <0>;
		rotation = <0>;

		clocks = <&camcc CAM_CC_MCLK3_CLK>;
		assigned-clocks = <&camcc CAM_CC_MCLK3_CLK>;
		assigned-clock-rates = <19200000>;
		power-domains = <&camcc CAM_CC_TITAN_TOP_GDSC>;

		reset-gpios = <&tlmm 109 GPIO_ACTIVE_LOW>;
		pinctrl-0 = <&cam3_default>, <&cam3_reset_active>;
		pinctrl-1 = <&cam3_sleep>, <&cam3_reset_suspend>;
		pinctrl-names = "default", "sleep";

		dovdd-supply = <&camera_ldo7>;
		avdd-supply = <&camera_ldo3>;
		dvdd-supply = <&camera_ldo2>;

		port {
			lapis_front_cam_ep: endpoint {
				clock-lanes = <7>;
				data-lanes = <0 1 2 3>;
				link-frequencies = /bits/ 64 <595200000 297600000>;
				remote-endpoint = <&lapis_csiphy0_ep>;
			};
		};
	};
};

/*
 * Rear torch on PM8550. The vendor camera uses flash channels 0 and 3
 * together (torch_0 + torch_3, switch mask 0x09). Channels 1 and 2 are
 * the other pair and are not the back torch.
 */
&pm8550_flash {
	status = "okay";

	rear_flash: led-0 {
		function = LED_FUNCTION_FLASH;
		color = <LED_COLOR_ID_WHITE>;
		led-sources = <1 4>;
		led-max-microamp = <400000>;
		flash-max-microamp = <1500000>;
		flash-max-timeout-us = <1280000>;
	};
};

&pm8550b_eusb2_repeater {
	vdd18-supply = <&vreg_l15b_1p8>;
	vdd3-supply = <&vreg_l5b_3p1>;
};

&pm8550vs_c {
	status = "okay";
};

&pm8550vs_d {
	status = "okay";
};

&pm8550vs_e {
	status = "okay";
};

&pm8550vs_g {
	status = "okay";
};

&pon_pwrkey {
	status = "okay";
};

&pon_resin {
	linux,code = <KEY_VOLUMEDOWN>;

	status = "okay";
};

/* QUPv3 WRAP1 (0xac0000): hosts &i2c3, &spi4, &i2c6, &i2c7 */
&qupv3_id_0 {
	status = "okay";
};

/* QUPv3 WRAP2 (0x8c0000): hosts &uart10 (pogo keyboard) and &uart14 (BT) */
&qupv3_id_1 {
	status = "okay";

	/*
	 * QUPv3 WRAP2 SE2 (0x888000 / downstream qupv3_se10_uart):
	 * Lenovo 2-in-1 Pogo-Pin Keyboard & Trackpad One-Wire Bus PPP UART.
	 * Downstream GPIOs (dtbo_37.dts fragment@38):
	 *   uart-tx = gpio10, uart-rx = gpio11 (qup2_se2)
	 *   power-en = gpio173, plug = gpio198, uart-wake = gpio171,
	 *   tx-en = gpio119, pupd = gpio180
	 */
	uart10: serial@888000 {
		compatible = "qcom,geni-uart";
		reg = <0x0 0x00888000 0x0 0x4000>;
		interrupts = <GIC_SPI 584 IRQ_TYPE_LEVEL_HIGH 0>;
		clocks = <&gcc GCC_QUPV3_WRAP2_S2_CLK>;
		clock-names = "se";
		interconnects = <&clk_virt MASTER_QUP_CORE_2 QCOM_ICC_TAG_ALWAYS
				 &clk_virt SLAVE_QUP_CORE_2 QCOM_ICC_TAG_ALWAYS>,
				<&gem_noc MASTER_APPSS_PROC QCOM_ICC_TAG_ACTIVE_ONLY
				 &config_noc SLAVE_QUP_2 QCOM_ICC_TAG_ACTIVE_ONLY>;
		interconnect-names = "qup-core", "qup-config";
		power-domains = <&rpmhpd RPMHPD_CX>;
		operating-points-v2 = <&qup_opp_table_100mhz>;
		pinctrl-0 = <&pogo_kb_uart_default>;
		pinctrl-names = "default";
		status = "okay";

		keyboard {
			compatible = "lenovo,tb520fu-pogo-keyboard";
			power-gpios = <&tlmm 173 GPIO_ACTIVE_HIGH>;
			tx-en-gpios = <&tlmm 119 GPIO_ACTIVE_HIGH>;
			plug-gpios = <&tlmm 198 GPIO_ACTIVE_LOW>;
		};
	};
};

&remoteproc_adsp {
	firmware-name = "qcom/sm8650/lenovo/tb520fu/adsp.mbn",
			"qcom/sm8650/lenovo/tb520fu/adsp_dtb.mbn";

	status = "okay";
};

&remoteproc_cdsp {
	firmware-name = "qcom/sm8650/lenovo/tb520fu/cdsp.mbn",
			"qcom/sm8650/lenovo/tb520fu/cdsp_dtb.mbn";

	status = "okay";
};

&rpmhpd {
	qcom,domain-performance-state-floors =
		<RPMHPD_MMCX RPMH_REGULATOR_LEVEL_SVS>;
};

&sleep_clk {
	clock-frequency = <32000>;
};

/*
 * QUPv3 WRAP1 SE4 (0xa90000):
 * Novatek NT36532 Touchscreen + Lenovo Tab Pen Pro over SPI (spi0.0)
 * Note: Panel is natively landscape (2944x1840, 274x171 mm), while Novatek
 * touch reports portrait coordinates rotated 90 degrees (BoardConfig: ROTATION_RIGHT).
 */
&spi4 {
	status = "okay";

	touchscreen@0 {
		compatible = "novatek,nt36532e";
		reg = <0>;

		interrupts-extended = <&tlmm 162 IRQ_TYPE_EDGE_FALLING>;
		reset-gpios = <&tlmm 161 GPIO_ACTIVE_LOW>;

		spi-max-frequency = <9600000>;

		panel = <&panel>;
		novatek,pen-support;
		novatek,pen-max-pressure = <4095>;
		novatek,pen-max-tilt = <60>;
		firmware-name = "novatek/novatek_ts_tianma_fw.bin";

		touchscreen-size-x = <18400>;
		touchscreen-size-y = <29440>;
		touchscreen-max-pressure = <1000>;
		touchscreen-x-mm = <171>;
		touchscreen-y-mm = <274>;
		touchscreen-swapped-x-y;
		touchscreen-inverted-x;

		pinctrl-0 = <&ts_default>;
		pinctrl-names = "default";
	};
};

&lpass_wsa2macro {
	status = "disabled";
};

&lpass_wsamacro {
	status = "disabled";
};

&lpass_rxmacro {
	status = "okay";
};

&lpass_txmacro {
	status = "okay";
};

&lpass_vamacro {
	qcom,dmic-sample-rate = <600000>;
	status = "okay";
};

&q6apmbedai {
	#address-cells = <1>;
	#size-cells = <0>;

	pinctrl-0 = <&tdm1_active>;
	pinctrl-1 = <&tdm1_sleep>;
	pinctrl-names = "default", "sleep";

	dai@28 {
		reg = <SECONDARY_TDM_RX_0>;
		clocks = <&q6prmcc LPASS_CLK_ID_SEC_TDM_IBIT
				   LPASS_CLK_ATTRIBUTE_COUPLE_NO>;
		clock-names = "bclk";
	};
};

&swr1 {
	status = "okay";

	wcd_rx: codec@0,4 {
		compatible = "sdw20217010e00";
		reg = <0 4>;
		qcom,rx-port-mapping = <1 2 3 4 5 9>;
	};
};

&swr2 {
	status = "okay";

	qcom,dout-ports = <0>;
	qcom,ports-sinterval-low =	/bits/ 8 <0x01 0x01 0x03 0x03>;
	qcom,ports-offset1 =		/bits/ 8 <0x00 0x00 0x01 0x01>;
	qcom,ports-offset2 =		/bits/ 8 <0x00 0x00 0x00 0x00>;
	qcom,ports-hstart =		/bits/ 8 <0xff 0xff 0xff 0xff>;
	qcom,ports-hstop =		/bits/ 8 <0xff 0xff 0xff 0xff>;
	qcom,ports-word-length =	/bits/ 8 <0xff 0xff 0xff 0xff>;
	qcom,ports-block-pack-mode =	/bits/ 8 <0xff 0xff 0xff 0xff>;
	qcom,ports-block-group-count =	/bits/ 8 <0xff 0xff 0xff 0xff>;
	qcom,ports-lane-control =	/bits/ 8 <0x01 0x02 0x00 0x00>;

	wcd_tx: codec@0,3 {
		compatible = "sdw20217010e00";
		reg = <0 3>;
		qcom,tx-port-mapping = <2 2 3 4>;
	};
};

&tlmm {
	gpio-reserved-ranges = <36 4>, <74 1>;

	fp_default: fp-default-state {
		pins = "gpio91", "gpio92";
		function = "gpio";
		drive-strength = <2>;
		bias-disable;
	};

	pen_hall_default: pen-hall-default-state {
		pins = "gpio177";
		function = "gpio";
		drive-strength = <2>;
		bias-pull-up;
		input-enable;
	};

	camera_pmic_default: camera-pmic-default-state {
		pins = "gpio5";
		function = "gpio";
		bias-disable;
		drive-strength = <2>;
	};

	cam0_reset_active: cam0-reset-active-state {
		pins = "gpio7";
		function = "gpio";
		drive-strength = <2>;
		bias-disable;
		output-low;
	};

	cam0_reset_suspend: cam0-reset-suspend-state {
		pins = "gpio7";
		function = "gpio";
		drive-strength = <2>;
		bias-pull-down;
		input-enable;
	};

	cam3_reset_active: cam3-reset-active-state {
		pins = "gpio109";
		function = "gpio";
		drive-strength = <2>;
		bias-disable;
		output-low;
	};

	cam3_reset_suspend: cam3-reset-suspend-state {
		pins = "gpio109";
		function = "gpio";
		drive-strength = <2>;
		bias-pull-down;
		input-enable;
	};

	folio_hall_default: folio-hall-default-state {
		pins = "gpio182";
		function = "gpio";
		drive-strength = <2>;
		bias-pull-up;
		input-enable;
	};

	amp_grp0_rst_default: amp-grp0-rst-default-state {
		pins = "gpio128";
		function = "gpio";
		drive-strength = <8>;
		bias-disable;
		output-high;
	};

	amp_grp1_rst_default: amp-grp1-rst-default-state {
		pins = "gpio28";
		function = "gpio";
		drive-strength = <8>;
		bias-disable;
		output-high;
	};

	wcd_default: wcd-reset-n-active-state {
		pins = "gpio107";
		function = "gpio";
		drive-strength = <16>;
		bias-disable;
		output-low;
	};

	tdm1_active: tdm1-active-state {
		clk-pins {
			pins = "gpio121";
			function = "i2s1_sck";
			drive-strength = <8>;
			bias-disable;
			output-high;
		};

		data0-pins {
			pins = "gpio122";
			function = "i2s1_data0";
			drive-strength = <8>;
			bias-disable;
		};

		ws-pins {
			pins = "gpio123";
			function = "i2s1_ws";
			drive-strength = <8>;
			bias-disable;
			output-high;
		};

		data1-pins {
			pins = "gpio124";
			function = "i2s1_data1";
			drive-strength = <8>;
			bias-pull-down;
		};
	};

	tdm1_sleep: tdm1-sleep-state {
		pins = "gpio121", "gpio122", "gpio123", "gpio124";
		function = "gpio";
		drive-strength = <2>;
		bias-pull-down;
		input-enable;
	};

	bt_default: bt-default-state {
		bt-en-pins {
			pins = "gpio17";
			function = "gpio";
			drive-strength = <16>;
			bias-disable;
		};

		sw-ctrl-pins {
			pins = "gpio18";
			function = "gpio";
			bias-pull-down;
		};
	};

	disp_reset_n_active: disp-reset-n-active-state {
		pins = "gpio133";
		function = "gpio";
		drive-strength = <8>;
		bias-disable;
	};

	mdp_vsync_active: mdp-vsync-active-state {
		pins = "gpio86";
		function = "mdp_vsync";
		drive-strength = <2>;
		bias-pull-down;
	};

	pogo_kb_uart_default: pogo-kb-uart-default-state {
		tx-pins {
			pins = "gpio10";
			function = "qup2_se2";
			drive-strength = <8>;
			bias-disable;
		};

		rx-pins {
			pins = "gpio11";
			function = "qup2_se2";
			drive-strength = <2>;
			bias-disable;
		};

		ctrl-pins {
			pins = "gpio119", "gpio173", "gpio180";
			function = "gpio";
			drive-strength = <2>;
			bias-disable;
		};

		irq-pins {
			pins = "gpio171", "gpio198";
			function = "gpio";
			drive-strength = <2>;
			bias-pull-up;
			input-enable;
		};
	};

	ts_default: ts-default-state {
		pins = "gpio162";
		function = "gpio";
		drive-strength = <8>;
		bias-disable;
		input-enable;
	};

	wlan_en: wlan-en-state {
		pins = "gpio16";
		function = "gpio";
		drive-strength = <16>;
		bias-pull-down;
	};
};

&uart14 {
	status = "okay";

	bluetooth {
		compatible = "qcom,wcn7850-bt";

		vddrfacmn-supply = <&vreg_pmu_rfa_cmn>;
		vddaon-supply = <&vreg_pmu_aon_0p59>;
		vddwlcx-supply = <&vreg_pmu_wlcx_0p8>;
		vddwlmx-supply = <&vreg_pmu_wlmx_0p85>;
		vddrfa0p8-supply = <&vreg_pmu_rfa_0p8>;
		vddrfa1p2-supply = <&vreg_pmu_rfa_1p2>;
		vddrfa1p8-supply = <&vreg_pmu_rfa_1p8>;

		max-speed = <3200000>;
	};
};

/* UFS 4.0 Internal Storage (256 GB / 512 GB) */
&ufs_mem_hc {
	reset-gpios = <&tlmm 210 GPIO_ACTIVE_LOW>;

	vcc-supply = <&vreg_l17b_2p5>;
	vcc-max-microamp = <1300000>;
	vccq-supply = <&vreg_l1c_1p2>;
	vccq-max-microamp = <1200000>;

	status = "okay";
};

&ufs_mem_phy {
	vdda-phy-supply = <&vreg_l1d_0p88>;
	vdda-pll-supply = <&vreg_l3i_1p2>;

	status = "okay";
};

&usb_1 {
	dr_mode = "otg";
	mode-switch;
	usb-role-switch;

	status = "okay";
};

&usb_1_dwc3_hs {
	remote-endpoint = <&pmic_glink_hs_in>;
};

&usb_1_hsphy {
	vdd-supply = <&vreg_l1i_0p88>;
	vdda12-supply = <&vreg_l3i_1p2>;

	phys = <&pm8550b_eusb2_repeater>;

	status = "okay";
};

&usb_dp_qmpphy {
	vdda-phy-supply = <&vreg_l3i_1p2>;
	vdda-pll-supply = <&vreg_l3g_0p91>;

	status = "okay";
};

&usb_dp_qmpphy_out {
	remote-endpoint = <&pmic_glink_ss_in>;
};

&xo_board {
	clock-frequency = <76800000>;
};

/*
 * Optical Goodix under the display. The secure app goodixfp64 owns the SPI
 * bus; this node is only the supply, reset and finger interrupt.
 */
/ {
	fingerprint {
		compatible = "goodix,gf3626";

		interrupt-parent = <&tlmm>;
		interrupts = <92 IRQ_TYPE_EDGE_RISING>;

		reset-gpios = <&tlmm 91 GPIO_ACTIVE_LOW>;
		vdd-supply = <&vreg_l9b_2p96>;
		firmware-name = "goodixfp64";

		pinctrl-names = "default";
		pinctrl-0 = <&fp_default>;
	};
};

/*
 * The PMIC counter has no epoch. Android stores (unix - raw) in the RTCInfo
 * EFI variable and the driver applies it on read. The alarm IRQ stays with
 * the kernel so suspend can wake from this RTC.
 */
&pmk8550_rtc {
	qcom,uefi-rtc-info;
};
